# Z20K14xM register map
Vendor: Zhixin Semiconductor; Series: Z20K14xM; File version: 0.1.0
CPU: CM4 r0p1, little endian, no MPU, FPU, 4 interrupt priority bits
Registers are 32-bit, read-write, reset 0x0 unless marked. A register's access mark holds for its fields unless they carry their own. Offsets are from the block's base; [hi:lo] are bit positions; {n}, {i} and the like mark numbered series.

## UART0
Base 0x4006A000
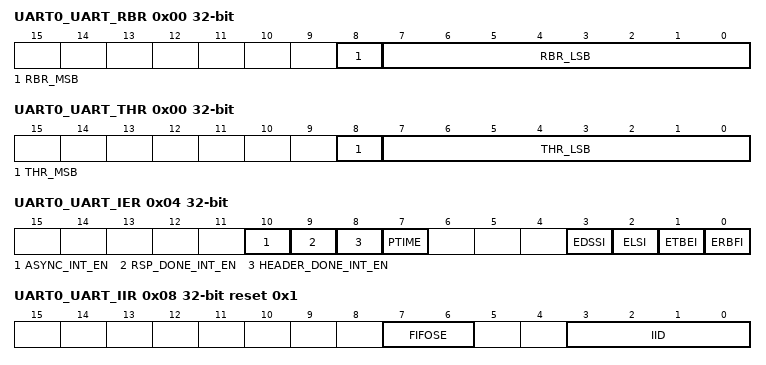
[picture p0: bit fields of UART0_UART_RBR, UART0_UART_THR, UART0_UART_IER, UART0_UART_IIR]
0x00 UART0_UART_RBR ro — Receive Buffer Register(LIN_RBR)
  [8] RBR_MSB — 9th bit of rbr
  [7:0] RBR_LSB — low 8bits of rbr
0x00 UART0_UART_THR ro — Receive Buffer Register(LIN_RBR)
  [8] THR_MSB — the 9bit of Data to be transmitted
  [7:0] THR_LSB — low 8bits of thr
0x00 UART0_UART_DLL ro — Receive Buffer Register(LIN_RBR)
  [7:0] DL_L — low 8bits of divisor register
0x04 UART0_UART_DLH — Divisor Latch High(LIN_DLH)
  [7:0] DL_H — high 8 bits of divisor register
0x04 UART0_UART_IER — Divisor Latch High(LIN_DLH)
  [10] ASYNC_INT_EN — Async interrupt enable
  [9] RSP_DONE_INT_EN — response operation done interrupt enable
  [8] HEADER_DONE_INT_EN — header operation done interrupt enable
  [7] PTIME — Programmable THRE Interrupt Mode Enable
  [3] EDSSI — Enable Modem Status Interrupt
  [2] ELSI — Enable Receiver Line Status Interrupt.
  [1] ETBEI — Enable Transmit Holding Register Empty Interrupt
  [0] ERBFI — Enable Received Data Available Interrupt
0x08 UART0_UART_IIR ro reset 0x1 — Interrupt Identity Register(LIN_IIR)
  [7:6] FIFOSE — FIFOs Enabled
  [3:0] IID — Interrupt ID
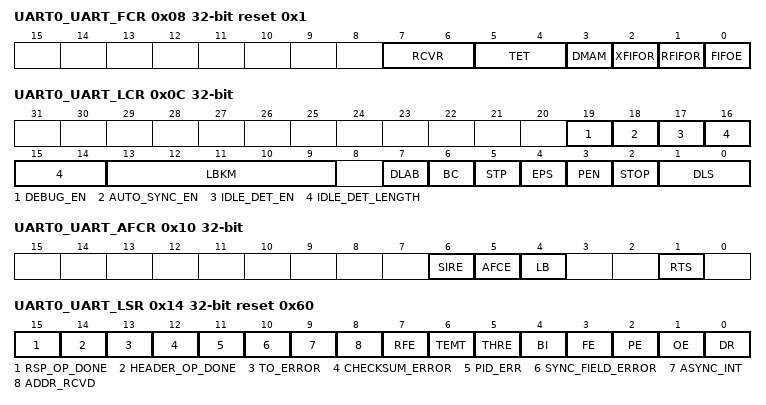
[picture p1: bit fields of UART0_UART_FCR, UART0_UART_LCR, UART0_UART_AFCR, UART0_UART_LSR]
0x08 UART0_UART_FCR ro reset 0x1 — Interrupt Identity Register(LIN_IIR)
  [7:6] RCVR — receiver interrupt trigger
  [5:4] TET — transmit empty threshold
  [3] DMAM — DMA Mode
  [2] XFIFOR — XMIT FIFO Reset
  [1] RFIFOR — RCVR FIFO Reset
  [0] FIFOE — FIFO Enable
0x0C UART0_UART_LCR — LIN Control Register(LIN_LCR)
  [19] DEBUG_EN — debug enable
  [18] AUTO_SYNC_EN — LIN baudrate auto sync enable
  [17] IDLE_DET_EN — idle detect enable
  [16:14] IDLE_DET_LENGTH — idle detect lendth
  [13:9] LBKM — the length of break in LIN mode
  [7] DLAB — Divisor Latch Access Bit
  [6] BC — Break Control Bit
  [5] STP — Stick Parity
  [4] EPS — Even Parity Select
  [3] PEN — Parity Enable.
  [2] STOP — Number of stop bits.
  [1:0] DLS — Data Length Select
0x10 UART0_UART_AFCR — Autoflow Control Register(LIN_AFCR)
  [6] SIRE — SIR Mode Enable
  [5] AFCE — Auto Flow Control Enable
  [4] LB — LoopBack Bit
  [1] RTS — Request to Send
0x14 UART0_UART_LSR ro reset 0x60 — Line Status Register(LIN_LSR)
  [15] RSP_OP_DONE — response operation done flag
  [14] HEADER_OP_DONE — header operation done flag
  [13] TO_ERROR — timeout error
  [12] CHECKSUM_ERROR — checksum error flag
  [11] PID_ERR — PID error
  [10] SYNC_FIELD_ERROR
  [9] ASYNC_INT — Async interrupt flag
  [8] ADDR_RCVD — Address Received bit
  [7] RFE — Receiver FIFO Error bit
  [6] TEMT — Transmitter Empty bit.
  [5] THRE — Transmit Holding Register Empty bit
  [4] BI — Break Interrupt bit
  [3] FE — Framing Error bit.
  [2] PE — Parity Error bit.
  [1] OE — Overrun error bit
  [0] DR — Data Ready bit
0x18 UART0_UART_MSR ro — Modem Status Register(LIN_MSR)
  [4] CTS — clear to send
0x7C UART0_UART_USR ro — UART Status Register(LIN_USR)
  [0] BUSY — UART Busy.
0xA8 UART0_UART_DMA_SA wo — DMA Software Acknowledge(LIN_DMA_SA)
  [0] DMA_SA — Reserved
0xC0 UART0_UART_FD — fraction divisor register(LIN_FD)
  [3:0] FD — Fractional divisor.
0xC4 UART0_UART_RAR — Receive Address Register (LIN_RAR)
  [7:0] RAR — address matching
0xC8 UART0_UART_TAR — Transmit Address Register(LIN_TAR)
  [7:0] TAR — address matching register during transmit mode
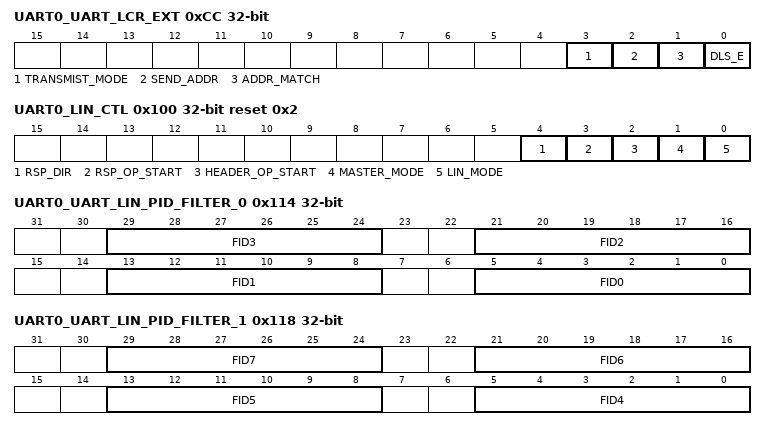
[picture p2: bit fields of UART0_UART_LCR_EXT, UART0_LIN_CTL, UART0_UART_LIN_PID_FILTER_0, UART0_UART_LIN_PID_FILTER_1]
0xCC UART0_UART_LCR_EXT — Line Extended Control Register(LIN_LCR_EXT)
  [3] TRANSMIST_MODE — Transmit mode control bit
  [2] SEND_ADDR — Send address control bit
  [1] ADDR_MATCH — Address Match Mode.
  [0] DLS_E — Extension for DLS
0x100 UART0_LIN_CTL reset 0x2 — LIN mode control register(LIN_CTL)
  [4] RSP_DIR — response operation direction
  [3] RSP_OP_START — response operation start trigger
  [2] HEADER_OP_START — header operation start trigger
  [1] MASTER_MODE
  [0] LIN_MODE — LIN mode enable
0x104 UART0_UART_LIN_RSP_LENGTH — LIN response length register(LIN_RSP_LENGTH)
  [3:0] RSP_LENGTH — LIN response length register
0x108 UART0_UART_LIN_PID_VALUE — LIN PID register(LIN_PID_VALUE)
  [5:0] PID — LIN PID register
0x10C UART0_UART_LIN_CHECKSUM — LIN checksum register(LIN_CHECKSUM)
  [0] CHECKSUM_TYPE — LIN checksum type
0x110 UART0_UART_LIN_DEL_LENGTH — LIN delimiter field length(LIN_DEL_LENGTH)
  [2:0] LIN_DEL_LENGTH — LIN delimiter field length
0x114 UART0_UART_LIN_PID_FILTER_0 — LIN PID filter 0(LIN_PID_FILTER_0)
  [8n+5:8n] FID{n} (n=0..3) — filter PID{n}
0x118 UART0_UART_LIN_PID_FILTER_1 — LIN PID filter 1(LIN_PID_FILTER_1)
  [8n-27:8n-32] FID{n} (n=4..7) — filter PID{n}
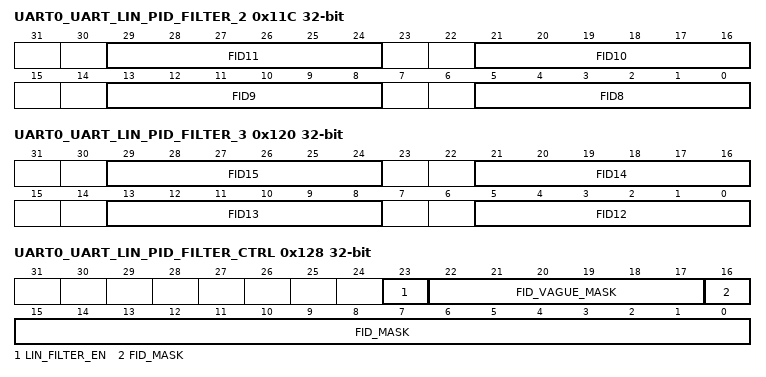
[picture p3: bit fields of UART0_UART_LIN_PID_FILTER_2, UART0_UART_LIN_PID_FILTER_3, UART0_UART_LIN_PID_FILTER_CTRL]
0x11C UART0_UART_LIN_PID_FILTER_2 — LIN PID filter 2(LIN_PID_FILTER_2)
  [8n-59:8n-64] FID{n} (n=8..11) — filter PID{n}
0x120 UART0_UART_LIN_PID_FILTER_3 — LIN PID filter 3(LIN_PID_FILTER_3)
  [8n-91:8n-96] FID{n} (n=12..15) — filter PID{n}
0x124 UART0_UART_LIN_PID_FILTER_VAGUE — LIN PID filter vague(LIN_PID_FILTER_VAGUE)
  [5:0] FID_VAGUE — vague filter PID
0x128 UART0_UART_LIN_PID_FILTER_CTRL — LIN PID filter ctrl register(LIN_PID_FILTER_CTRL)
  [23] LIN_FILTER_EN — the enable bit of the filter
  [22:17] FID_VAGUE_MASK — he enable bit of the filter vague id
  [16:0] FID_MASK — the enable bit of the filter id 0-15

## UART1
Base 0x4006B000
Registers as UART0 (with UART0 read as UART1).

## UART2
Base 0x4006C000
Registers as UART0 (with UART0 read as UART2).

## UART3
Base 0x40070000
Registers as UART0 (with UART0 read as UART3).

## UART4
Base 0x40071000
Registers as UART0 (with UART0 read as UART4).

## UART5
Base 0x40072000
Registers as UART0 (with UART0 read as UART5).
